# RTS5921 register map
Vendor: Realtek Semiconductor Corp.; Series: RTS5921 Series; File version: 0.01
CPU: ARMV8MBL r0p0, little endian, MPU, no FPU, VTOR, 3 interrupt priority bits
Registers are 32-bit, read-write, reset 0x0 unless marked. A register's access mark holds for its fields unless they carry their own. Offsets are from the block's base; [hi:lo] are bit positions; {n}, {i} and the like mark numbered series; 'fields as' and 'values as' point back to an identical list.

## SYSTEM — System Controller
Base 0x40100000
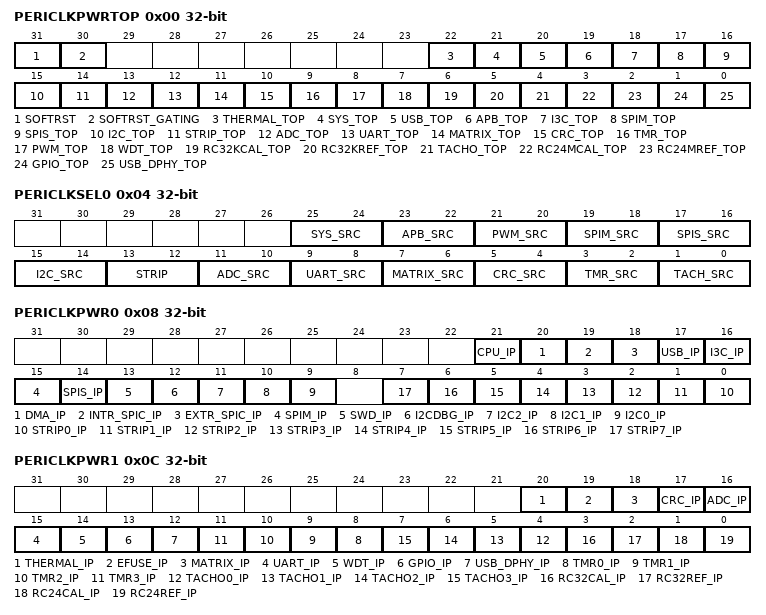
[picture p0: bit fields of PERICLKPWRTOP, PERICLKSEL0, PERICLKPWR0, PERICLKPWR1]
0x00 PERICLKPWRTOP — Peripheral Power Clock Control Register 0
  [31] SOFTRST — Software Reset (Write 1 to Clear)
    0=DISABLE; 1=ENABLE (Enable (write 1 to clear))
  [30] SOFTRST_GATING — Software Reset External Gating
    0=DISABLE; 1=ENABLE
  [22] THERMAL_TOP — Thermal Power Control
    0=DISABLE; 1=ENABLE
  [21] SYS_TOP — System Clock Power Control
    0=DISABLE; 1=ENABLE
  [20] USB_TOP — USB Clock Power Control
    0=DISABLE; 1=ENABLE
  [19] APB_TOP — APB Clock Power Control
    0=DISABLE; 1=ENABLE
  [18] I3C_TOP — I3C Clock Power Control
    0=DISABLE; 1=ENABLE
  [17] SPIM_TOP — SPI Master Clock Power Control
    0=DISABLE; 1=ENABLE
  [16] SPIS_TOP — SPI Slave Clock Power Control
    0=DISABLE; 1=ENABLE
  [15] I2C_TOP — I2C Clock Power Control
    0=DISABLE; 1=ENABLE
  [14] STRIP_TOP — Strip Clock Power Control
    0=DISABLE; 1=ENABLE
  [13] ADC_TOP — ADC Clock Power Control
    0=DISABLE; 1=ENABLE
  [12] UART_TOP — UART Clock Power Control
    0=DISABLE; 1=ENABLE
  [11] MATRIX_TOP — Matrix Clock Power Control
    0=DISABLE; 1=ENABLE
  [10] CRC_TOP — CRC Clock Power Control
    0=DISABLE; 1=ENABLE
  [9] TMR_TOP — Timer Clock Power Control
    0=DISABLE; 1=ENABLE
  [8] PWM_TOP — PWM Clock Power Control
    0=DISABLE; 1=ENABLE
  [7] WDT_TOP — Watchdog Timer Clock Power Control
    0=DISABLE; 1=ENABLE
  [6] RC32KCAL_TOP — RC 32K Cal Clock Power Control
    0=DISABLE; 1=ENABLE
  [5] RC32KREF_TOP — RC 32K Ref Clock Power Control
    0=DISABLE; 1=ENABLE
  [4] TACHO_TOP — Tachometer Clock Power Control
    0=DISABLE; 1=ENABLE
  [3] RC24MCAL_TOP — RC 24M Cal Clock Power Control
    0=DISABLE; 1=ENABLE
  [2] RC24MREF_TOP — RC 24M Ref Clock Power Control
    0=DISABLE; 1=ENABLE
  [1] GPIO_TOP — IO Clock Power Control
    0=DISABLE; 1=ENABLE
  [0] USB_DPHY_TOP — USB DPHY Clock Power Control
    0=DISABLE; 1=ENABLE
0x04 PERICLKSEL0
  [25:24] SYS_SRC — System Clock Source Select
    0=PLL60M (From PLL60M); 1=XTAL24M (From XTAL24M); 2=RC24M (From RC24M)
  [23:22] APB_SRC — Async Bus Clock Source Select
    values as SYS_SRC
  [21:20] PWM_SRC — PWM Clock Source Select
    0=XTAL24M (From XTAL24M); 1=RC24M (From RC24M); 2=RC32K (From RC32K)
  [19:18] SPIM_SRC — SPI Master Clock Source Select
    values as SYS_SRC
  [17:16] SPIS_SRC — SPI Slave Clock Source Select
    values as SYS_SRC
  [15:14] I2C_SRC — I2C Clock Source Select
    values as SYS_SRC
  [13:12] STRIP — STRIP Clock Source Select
    values as SYS_SRC
  [11:10] ADC_SRC — ADC Clock Source Select
    values as SYS_SRC
  [9:8] UART_SRC — UART Clock Source Select
    values as SYS_SRC
  [7:6] MATRIX_SRC — Dot Matrix LED Clock Source Select
    values as SYS_SRC
  [5:4] CRC_SRC — CRC Source Select
    values as SYS_SRC
  [3:2] TMR_SRC — TMR Clock Source Select
    values as PWM_SRC
  [1:0] TACH_SRC — TACH Clock Source Select
    values as PWM_SRC
0x08 PERICLKPWR0 — Peripheral Clock Power Control Register 0
  [all] fields
    0=DISABLE; 1=ENABLE
  [21] CPU_IP — CPU clock enable: 0=Disable, 1=Enable
  [20] DMA_IP — DMA clock enable: 0=Disable, 1=Enable
  [19] INTR_SPIC_IP — INTR SPIC clock enable: 0=Disable, 1=Enable
  [18] EXTR_SPIC_IP — EXTR SPIC clock enable: 0=Disable, 1=Enable
  [17] USB_IP — USB clock enable: 0=Disable, 1=Enable
  [16] I3C_IP — I3C clock enable: 0=Disable, 1=Enable
  [15] SPIM_IP — SPIM clock enable: 0=Disable, 1=Enable
  [14] SPIS_IP — SPIS clock enable: 0=Disable, 1=Enable
  [13] SWD_IP — SWD clock enable: 0=Disable, 1=Enable
  [12] I2CDBG_IP — I2C Debug clock enable: 0=Disable, 1=Enable
  [11] I2C2_IP — I2C2 clock enable: 0=Disable, 1=Enable
  [10] I2C1_IP — I2C1 clock enable: 0=Disable, 1=Enable
  [9] I2C0_IP — I2C0 clock enable: 0=Disable, 1=Enable
  [n] STRIP{n}_IP (n=0..7) — STRIP{n} clock enable: 0=Disable, 1=Enable
0x0C PERICLKPWR1 — Peripheral Clock Power Control Register 1
  [all] fields
    0=DISABLE; 1=ENABLE
  [20] THERMAL_IP — THERMAL_IP clock enable: 0=Disable, 1=Enable
  [19] EFUSE_IP — EFUSE clock enable: 0=Disable, 1=Enable
  [18] MATRIX_IP — MATRIX clock enable: 0=Disable, 1=Enable
  [17] CRC_IP — CRC clock enable: 0=Disable, 1=Enable
  [16] ADC_IP — ADC clock enable: 0=Disable, 1=Enable
  [15] UART_IP — URAT clock enable: 0=Disable, 1=Enable
  [14] WDT_IP — WDT clock enable: 0=Disable, 1=Enable
  [13] GPIO_IP — IO clock enable: 0=Disable, 1=Enable
  [12] USB_DPHY_IP — USB_DPHY clock enable: 0=Disable, 1=Enable
  [n+8] TMR{n}_IP (n=0..3) — TMR{n} clock enable: 0=Disable, 1=Enable
  [n+4] TACHO{n}_IP (n=0..3) — TACHO{n} clock enable: 0=Disable, 1=Enable
  [3] RC32CAL_IP — RC32CAL clock enable: 0=Disable, 1=Enable
  [2] RC32REF_IP — RC32REF clock enable: 0=Disable, 1=Enable
  [1] RC24CAL_IP — RC24CAL clock enable: 0=Disable, 1=Enable
  [0] RC24REF_IP — RC24REF clock enable: 0=Disable, 1=Enable
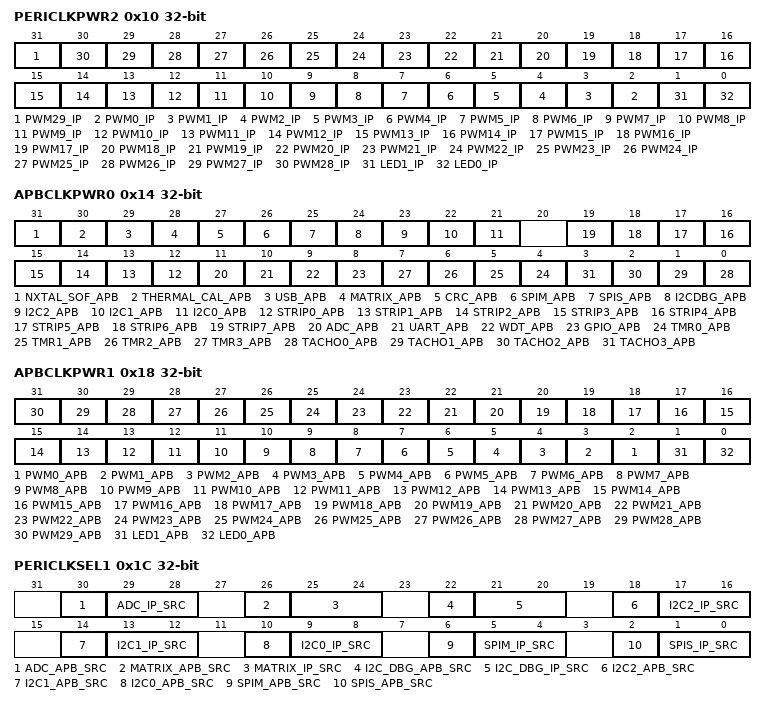
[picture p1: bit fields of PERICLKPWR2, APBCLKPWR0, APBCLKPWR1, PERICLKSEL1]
0x10 PERICLKPWR2 — Peripheral Clock Power Control Register 2
  [all] fields
    0=DISABLE; 1=ENABLE
  [31] PWM29_IP — PWM29_APB_SRC clock enable: 0=Disable, 1=Enable
  [n+2] PWM{n}_IP (n=0..28) — PWM{n} clock enable: 0=Disable, 1=Enable
  [1] LED1_IP — LED1 clock enable: 0=Disable, 1=Enable
  [0] LED0_IP — LED0 clock enable: 0=Disable, 1=Enable
0x14 APBCLKPWR0 — APB Clock Power Control Register 0
  [all] fields
    0=DISABLE; 1=ENABLE
  [31] NXTAL_SOF_APB — NXTAL Sof clock enable: 0=Disable, 1=Enable
  [30] THERMAL_CAL_APB — Thermal calibration clock enable: 0=Disable, 1=Enable
  [29] USB_APB — USB clock enable: 0=Disable, 1=Enable
  [28] MATRIX_APB — MATRIX clock enable: 0=Disable, 1=Enable
  [27] CRC_APB — CRC clock enable: 0=Disable, 1=Enable
  [26] SPIM_APB — SPIM clock enable: 0=Disable, 1=Enable
  [25] SPIS_APB — SPIS clock enable: 0=Disable, 1=Enable
  [24] I2CDBG_APB — I2C Debug clock enable: 0=Disable, 1=Enable
  [23] I2C2_APB — I2C2 clock enable: 0=Disable, 1=Enable
  [22] I2C1_APB — I2C1 clock enable: 0=Disable, 1=Enable
  [21] I2C0_APB — I2C0 clock enable: 0=Disable, 1=Enable
  [n+12] STRIP{n}_APB (n=0..7) — STRIP{n} clock enable: 0=Disable, 1=Enable
  [11] ADC_APB — ADC clock enable: 0=Disable, 1=Enable
  [10] UART_APB — UART clock enable: 0=Disable, 1=Enable
  [9] WDT_APB — WDT clock enable: 0=Disable, 1=Enable
  [8] GPIO_APB — IO clock enable: 0=Disable, 1=Enable
  [n+4] TMR{n}_APB (n=0..3) — TMR{n} clock enable: 0=Disable, 1=Enable
  [n] TACHO{n}_APB (n=0..3) — TACHO{n} clock enable: 0=Disable, 1=Enable
0x18 APBCLKPWR1 — APB Clock Power Control Register 1
  [all] fields
    0=DISABLE; 1=ENABLE
  [n+2] PWM{n}_APB (n=0..29) — PWM{n} clock enable: 0=Disable, 1=Enable
  [1] LED1_APB — LED1 clock enable: 0=Disable, 1=Enable
  [0] LED0_APB — LED0 clock enable: 0=Disable, 1=Enable
0x1C PERICLKSEL1 — Clock Source Select for CTS1 IP
  [30] ADC_APB_SRC — ADC Async Bus Clock Source Select
    0=60M; 1=30M
  [29:28] ADC_IP_SRC — ADC Control Clock Source Select
    values as PERICLKSEL0.SYS_SRC
  [26] MATRIX_APB_SRC — Dot Matrix LED Async Bus Clock Source Select
    0=60M; 1=30M
  [25:24] MATRIX_IP_SRC — Dot Matrix LED IP Clock Source Select
    values as PERICLKSEL0.SYS_SRC
  [22] I2C_DBG_APB_SRC — I2C Debug Async Bus Clock Source Select
    0=60M; 1=30M
  [21:20] I2C_DBG_IP_SRC — I2C Debug Clock Source Select
    values as PERICLKSEL0.SYS_SRC
  [18] I2C2_APB_SRC — I2C IP 2 Async Bus Clock Source Select
    0=60M; 1=30M
  [17:16] I2C2_IP_SRC — I2C IP 2 Clock Source Select
    values as PERICLKSEL0.SYS_SRC
  [14] I2C1_APB_SRC — I2C IP 1 Async Bus Clock Source Select
    0=60M; 1=30M
  [13:12] I2C1_IP_SRC — I2C IP 1 Clock Source Select
    values as PERICLKSEL0.SYS_SRC
  [10] I2C0_APB_SRC — I2C IP 0 Async Bus Clock Source Select
    0=60M; 1=30M
  [9:8] I2C0_IP_SRC — I2C IP 0 Clock Source Select
    values as PERICLKSEL0.SYS_SRC
  [6] SPIM_APB_SRC — SPI Master IP 0 Async Bus Clock Source Select
    0=60M; 1=30M
  [5:4] SPIM_IP_SRC — SPI Master IP 0 Clock Source Select
    values as PERICLKSEL0.SYS_SRC
  [2] SPIS_APB_SRC — SPI Slave IP 0 Async Bus Clock Source Select
    0=60M; 1=30M
  [1:0] SPIS_IP_SRC — SPI Slave IP 0 Clock Source Select
    values as PERICLKSEL0.SYS_SRC
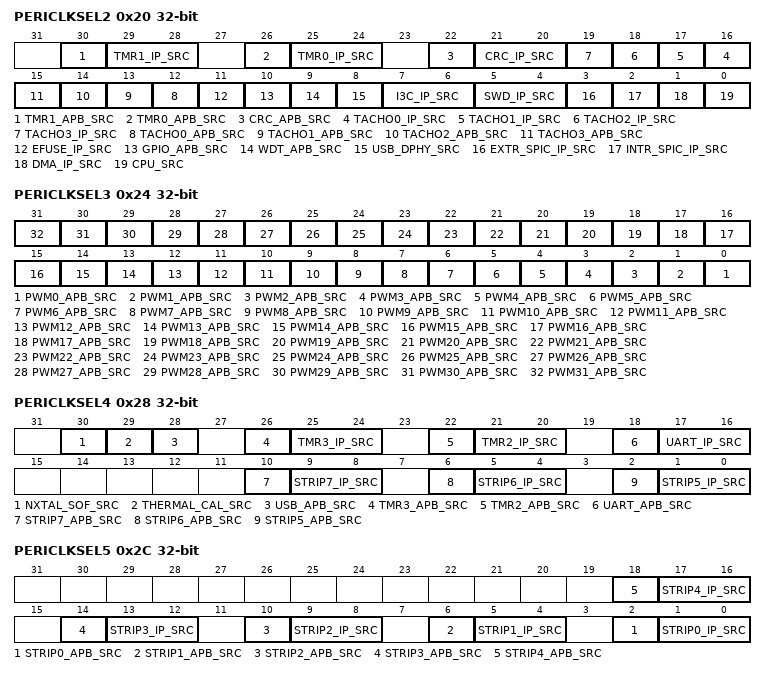
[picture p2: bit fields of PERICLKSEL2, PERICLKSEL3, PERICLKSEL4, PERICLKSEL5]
0x20 PERICLKSEL2 — Peripheral Clock Select Register 2
  [30] TMR1_APB_SRC — Timer IP 1 Async Bus Clock Source Select
    0=60M; 1=30M
  [29:28] TMR1_IP_SRC — Timer IP 1 Clock Source Select
    values as PERICLKSEL0.PWM_SRC
  [26] TMR0_APB_SRC — Timer IP 0 Async Bus Clock Source Select
    0=60M; 1=30M
  [25:24] TMR0_IP_SRC — Timer IP 0 Clock Source Select
    values as PERICLKSEL0.PWM_SRC
  [22] CRC_APB_SRC — Turbo Memory Comparator Async Bus Clock Source Select
    0=60M; 1=30M
  [21:20] CRC_IP_SRC — Turbo Memory Comparator IP Clock Source Select
    values as PERICLKSEL0.SYS_SRC
  [n+16] TACHO{n}_IP_SRC (n=0..3) — TACH IP {n} Clock Source Select
    0=XTAL24M (From XTAL24M); 1=RC24M (From RC24M)
  [n+12] TACHO{n}_APB_SRC (n=0..3) — TACH IP {n} Async Bus Clock Source Select
    0=60M; 1=30M
  [11] EFUSE_IP_SRC — eFuse Clock Source Select
  [10] GPIO_APB_SRC — GPIO Async Bus Clock Source Select
    0=60M; 1=30M
  [9] WDT_APB_SRC — WDT Async Bus Clock Source Select
    0=60M; 1=30M
  [8] USB_DPHY_SRC — USB DPHY IP Clock Source Select
  [7:6] I3C_IP_SRC — I3C IP Clock Source Select
  [5:4] SWD_IP_SRC — SWD Clock Source Select
  [3] EXTR_SPIC_IP_SRC — SPIC EXTR Clock Source Select
    0=60M; 1=24M
  [2] INTR_SPIC_IP_SRC — SPIC INTR Clock Source Select
    0=60M; 1=24M
  [1] DMA_IP_SRC — DMA Clock Source Select
  [0] CPU_SRC — CPU Clock Source Select
0x24 PERICLKSEL3 — Peripheral Clock Select Register 3
  [all] fields
    0=60M; 1=24M
  [n] PWM{n}_APB_SRC (n=0..31) — Clock source select for LED async bus[{n}]
0x28 PERICLKSEL4 — Peripheral Clock Select Register 4
  [30] NXTAL_SOF_SRC — Clock source select for NXTAL sof async bus
    0=60M; 1=24M
  [29] THERMAL_CAL_SRC — Clock source select for thermal calibration async bus
    0=60M; 1=24M
  [28] USB_APB_SRC — Clock source select for USB async bus
    0=60M; 1=24M
  [26] TMR3_APB_SRC — Clock source select for Timer IP3 async bus
    0=60M; 1=24M
  [25:24] TMR3_IP_SRC — Clock source select for Timer IP3
    values as PERICLKSEL0.PWM_SRC
  [22] TMR2_APB_SRC — Clock source select for Timer IP2 async bus
    0=60M; 1=24M
  [21:20] TMR2_IP_SRC — Clock source select for Timer IP2
    values as PERICLKSEL0.PWM_SRC
  [18] UART_APB_SRC — Clock source select for UART async bus
    0=60M; 1=24M
  [17:16] UART_IP_SRC — Clock source select for UART
    values as PERICLKSEL0.SYS_SRC
  [10] STRIP7_APB_SRC — Clock source select for strip IP[7] async bus
    0=60M; 1=24M
  [9:8] STRIP7_IP_SRC — Clock source select for strip IP[7]
    values as PERICLKSEL0.SYS_SRC
  [6] STRIP6_APB_SRC — Clock source select for strip IP[6] async bus
    0=60M; 1=24M
  [5:4] STRIP6_IP_SRC — Clock source select for strip IP[6]
    values as PERICLKSEL0.SYS_SRC
  [2] STRIP5_APB_SRC — Clock source select for strip IP[5] async bus
    0=60M; 1=24M
  [1:0] STRIP5_IP_SRC — Clock source select for strip IP[5]
    values as PERICLKSEL0.SYS_SRC
0x2C PERICLKSEL5 — Peripheral Clock Select Register 5
  [4n+2] STRIP{n}_APB_SRC (n=0..4) — Clock source select for strip IP[{n}] async bus
    0=60M; 1=24M
  [4n+1:4n] STRIP{n}_IP_SRC (n=0..4) — Clock source select for strip IP[{n}]
    values as PERICLKSEL0.SYS_SRC
{0x30+4i} PERIRST{i} (i=0..8) — PERIPHERAL RESET CONTROL REGISTER #{i}
0x54 CPUINITADDR0 — CPU INITIAL ADDRESS REGISTER #0
0x58 CPUINITADDR1 — CPU INITIAL ADDRESS REGISTER #1
0x5C SLEEPCTRL — SLEEP CONTROL REGISTER
0x60 ADCCLKCTRL — ADC CLOCK CONTROL REGISTER
0x64 USBCTRL — FPGA USB CONTROL REGISTER
